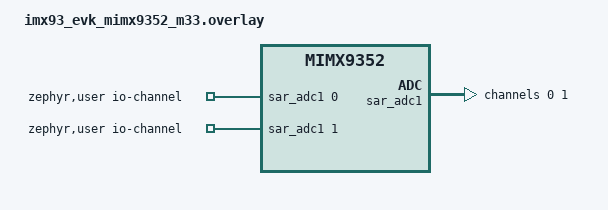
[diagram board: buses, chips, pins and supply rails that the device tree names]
/*
 * SPDX-License-Identifier: Apache-2.0
 *
 * Copyright 2025 NXP
 */

#include <zephyr/dt-bindings/adc/adc.h>

/ {
	zephyr,user {
		io-channels = <&sar_adc1 0>, <&sar_adc1 1>;
	};
};

&sar_adc1 {
	#address-cells = <1>;
	#size-cells = <0>;

	channel@0 {
		reg = <0>;
		zephyr,gain = "ADC_GAIN_1";
		zephyr,reference = "ADC_REF_VDD_1";
		zephyr,acquisition-time = <ADC_ACQ_TIME_DEFAULT>;
		zephyr,vref-mv = <3300>;
		zephyr,resolution = <12>;
		zephyr,input-positive = <0>;
	};

	channel@1 {
		reg = <1>;
		zephyr,gain = "ADC_GAIN_1";
		zephyr,reference = "ADC_REF_VDD_1";
		zephyr,acquisition-time = <ADC_ACQ_TIME_DEFAULT>;
		zephyr,vref-mv = <3300>;
		zephyr,resolution = <12>;
		zephyr,input-positive = <1>;
	};
};
